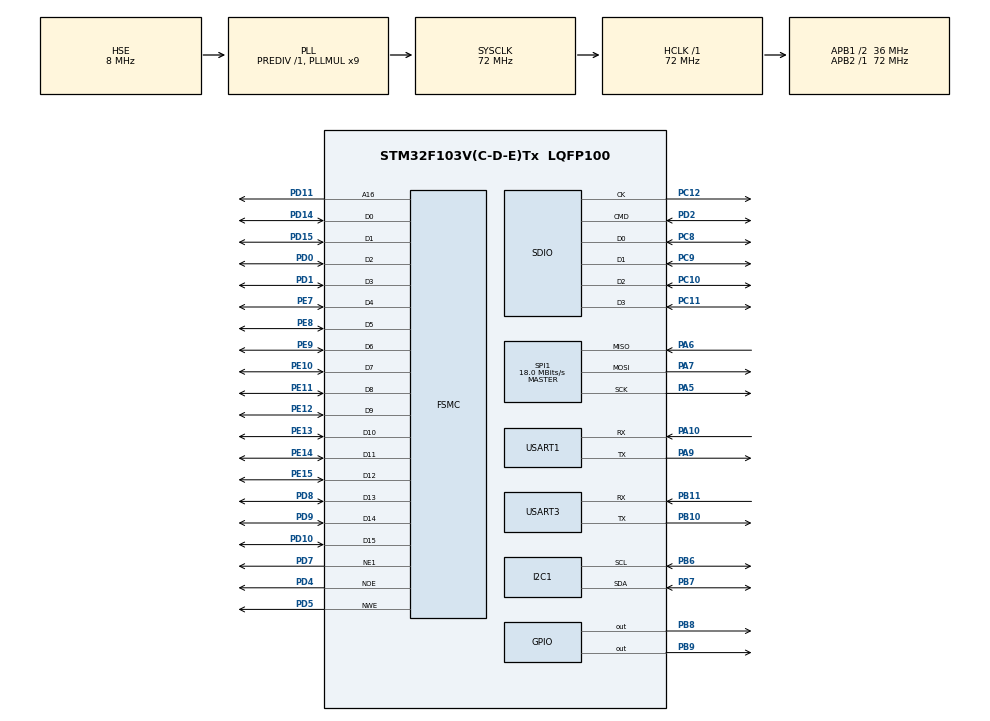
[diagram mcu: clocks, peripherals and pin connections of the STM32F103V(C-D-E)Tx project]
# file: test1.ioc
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Dma.MEMTOMEM.0.Direction=DMA_MEMORY_TO_MEMORY
Dma.MEMTOMEM.0.Instance=DMA1_Channel6
Dma.MEMTOMEM.0.MemDataAlignment=DMA_MDATAALIGN_HALFWORD
Dma.MEMTOMEM.0.MemInc=DMA_MINC_ENABLE
Dma.MEMTOMEM.0.Mode=DMA_NORMAL
Dma.MEMTOMEM.0.PeriphDataAlignment=DMA_PDATAALIGN_HALFWORD
Dma.MEMTOMEM.0.PeriphInc=DMA_PINC_ENABLE
Dma.MEMTOMEM.0.Priority=DMA_PRIORITY_VERY_HIGH
Dma.Request0=MEMTOMEM
Dma.Request1=SDIO
Dma.SDIO.1.Direction=DMA_PERIPH_TO_MEMORY
Dma.SDIO.1.Instance=DMA2_Channel4
Dma.SDIO.1.MemDataAlignment=DMA_MDATAALIGN_WORD
Dma.SDIO.1.MemInc=DMA_MINC_ENABLE
Dma.SDIO.1.Mode=DMA_NORMAL
Dma.SDIO.1.PeriphDataAlignment=DMA_PDATAALIGN_WORD
Dma.SDIO.1.PeriphInc=DMA_PINC_DISABLE
Dma.SDIO.1.Priority=DMA_PRIORITY_LOW
FATFS._FS_LOCK=4
FATFS._FS_REENTRANT=0
Mcu.Family=STM32F1
Mcu.Name=STM32F103V(C-D-E)Tx
Mcu.Package=LQFP100
NVIC.DMA1_Channel6_IRQn=true\:0\:0\:false\:false\:true\:true\:true\:true
NVIC.DMA2_Channel4_5_IRQn=true\:0\:0\:false\:false\:true\:false\:true\:true
NVIC.PriorityGroup=NVIC_PRIORITYGROUP_4
NVIC.RTC_IRQn=true\:0\:0\:false\:false\:true\:true\:true\:true
NVIC.SDIO_IRQn=true\:0\:0\:false\:false\:true\:true\:true\:true
NVIC.TIM1_UP_IRQn=true\:15\:0\:true\:false\:true\:false\:true\:true
NVIC.TimeBase=TIM1_UP_IRQn
NVIC.TimeBaseIP=TIM1
NVIC.USART3_IRQn=true\:0\:0\:false\:false\:true\:true\:true\:true
OSC_IN.Mode=HSE-External-Oscillator
OSC_IN.Signal=RCC_OSC_IN
OSC_OUT.Mode=HSE-External-Oscillator
OSC_OUT.Signal=RCC_OSC_OUT
PA10.Mode=Asynchronous
PA10.Signal=USART1_RX
PA13.Mode=Serial_Wire
PA13.Signal=SYS_JTMS-SWDIO
PA14.Mode=Serial_Wire
PA14.Signal=SYS_JTCK-SWCLK
PA5.Mode=Full_Duplex_Master
PA5.Signal=SPI1_SCK
PA6.Mode=Full_Duplex_Master
PA6.Signal=SPI1_MISO
PA7.Mode=Full_Duplex_Master
PA7.Signal=SPI1_MOSI
PA9.Mode=Asynchronous
PA9.Signal=USART1_TX
PB10.Mode=Asynchronous
PB10.Signal=USART3_TX
PB11.Mode=Asynchronous
PB11.Signal=USART3_RX
PB6.Mode=I2C
PB6.Signal=I2C1_SCL
PB7.Mode=I2C
PB7.Signal=I2C1_SDA
PB8.GPIO_PuPd=GPIO_PULLDOWN
PB8.GPIO_Speed=GPIO_SPEED_FREQ_HIGH
PB8.Signal=GPIO_Output
PB9.GPIO_PuPd=GPIO_PULLUP
PB9.GPIO_Speed=GPIO_SPEED_FREQ_HIGH
PB9.Signal=GPIO_Output
PC10.Mode=SD_4_bits_Wide_bus
PC10.Signal=SDIO_D2
PC11.Mode=SD_4_bits_Wide_bus
PC11.Signal=SDIO_D3
PC12.Mode=SD_4_bits_Wide_bus
PC12.Signal=SDIO_CK
PC14-OSC32_IN.Mode=LSE-External-Oscillator
PC14-OSC32_IN.Signal=RCC_OSC32_IN
PC15-OSC32_OUT.Mode=LSE-External-Oscillator
PC15-OSC32_OUT.Signal=RCC_OSC32_OUT
PC8.Mode=SD_4_bits_Wide_bus
PC8.Signal=SDIO_D0
PC9.Mode=SD_4_bits_Wide_bus
PC9.Signal=SDIO_D1
PD0.Mode=16b-d1
PD0.Signal=FSMC_D2
PD1.Mode=16b-d1
PD1.Signal=FSMC_D3
PD10.Mode=16b-d1
PD10.Signal=FSMC_D15
PD11.Mode=A16_1
PD11.Signal=FSMC_A16
PD14.Mode=16b-d1
PD14.Signal=FSMC_D0
PD15.Mode=16b-d1
PD15.Signal=FSMC_D1
PD2.Mode=SD_4_bits_Wide_bus
PD2.Signal=SDIO_CMD
PD4.Mode=Lcd1
PD4.Signal=FSMC_NOE
PD5.Mode=Lcd1
PD5.Signal=FSMC_NWE
PD7.Mode=NorPsramChipSelect1_1
PD7.Signal=FSMC_NE1
PD8.Mode=16b-d1
PD8.Signal=FSMC_D13
PD9.Mode=16b-d1
PD9.Signal=FSMC_D14
PE10.Mode=16b-d1
PE10.Signal=FSMC_D7
PE11.Mode=16b-d1
PE11.Signal=FSMC_D8
PE12.Mode=16b-d1
PE12.Signal=FSMC_D9
PE13.Mode=16b-d1
PE13.Signal=FSMC_D10
PE14.Mode=16b-d1
PE14.Signal=FSMC_D11
PE15.Mode=16b-d1
PE15.Signal=FSMC_D12
PE7.Mode=16b-d1
PE7.Signal=FSMC_D4
PE8.Mode=16b-d1
PE8.Signal=FSMC_D5
PE9.Mode=16b-d1
PE9.Signal=FSMC_D6
ProjectManager.HeapSize=0x200
ProjectManager.StackSize=0x400
ProjectManager.TargetToolchain=CMake
RCC.AHBFreq_Value=72000000
RCC.APB1CLKDivider=RCC_HCLK_DIV2
RCC.APB1Freq_Value=36000000
RCC.APB1TimFreq_Value=72000000
RCC.APB2Freq_Value=72000000
RCC.APB2TimFreq_Value=72000000
RCC.EnbaleCSS=true
RCC.HCLKFreq_Value=72000000
RCC.PLLMUL=RCC_PLL_MUL9
RCC.PLLSourceVirtual=RCC_PLLSOURCE_HSE
RCC.RTCClockSelection=RCC_RTCCLKSOURCE_LSE
RCC.SYSCLKFreq_VALUE=72000000
RCC.SYSCLKSource=RCC_SYSCLKSOURCE_PLLCLK
RCC.USBFreq_Value=72000000
RTC.Date=11
RTC.Format=RTC_FORMAT_BIN
RTC.Hours=22
RTC.Minutes=8
RTC.Month=RTC_MONTH_MARCH
RTC.WeekDay=RTC_WEEKDAY_WEDNESDAY
RTC.Year=26
SDIO.ClockBypass=SDIO_CLOCK_BYPASS_DISABLE
SDIO.ClockDiv=0
SDIO.ClockPowerSave=SDIO_CLOCK_POWER_SAVE_ENABLE
SDIO.HardwareFlowControl=SDIO_HARDWARE_FLOW_CONTROL_ENABLE
SPI1.BaudRatePrescaler=SPI_BAUDRATEPRESCALER_4
SPI1.CalculateBaudRate=18.0 MBits/s
SPI1.Direction=SPI_DIRECTION_2LINES
SPI1.Mode=SPI_MODE_MASTER
SPI1.VirtualType=VM_MASTER
USART1.VirtualMode=VM_ASYNC
USART3.VirtualMode=VM_ASYNC
VP_FATFS_VS_SDIO.Mode=SDIO
VP_RTC_VS_RTC_Activate.Mode=RTC_Enabled
VP_RTC_VS_RTC_Calendar.Mode=RTC_Calendar
VP_SYS_VS_tim1.Mode=TIM1
board=custom

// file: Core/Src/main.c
/* USER CODE BEGIN Header */
/**
  ******************************************************************************
  * @file           : main.c
  * @brief          : Main program body
  ******************************************************************************
  * @attention
  *
  * Copyright (c) 2025 STMicroelectronics.
  * All rights reserved.
  *
  * This software is licensed under terms that can be found in the LICENSE file
  * in the root directory of this software component.
  * If no LICENSE file comes with this software, it is provided AS-IS.
  *
  ******************************************************************************
  */
/* USER CODE END Header */
#include "main.h"
#include "dma.h"
#include "fatfs.h"
#include "i2c.h"
#include "rtc.h"
#include "sdio.h"
#include "spi.h"
#include "usart.h"
#include "gpio.h"
#include "fsmc.h"

/* USER CODE BEGIN Includes */
#include "log.h"
#include "string.h"
// #include "lvgl.h"
// #include "maze.h"
// #include "ESP8266.h"
/* USER CODE END Includes */

void SystemClock_Config(void);

int main(void)
{

  /* MCU Configuration--------------------------------------------------------*/

  /* Reset of all peripherals, Initializes the Flash interface and the Systick. */
  HAL_Init();

  /* Configure the system clock */
  SystemClock_Config();

  /* Initialize all configured peripherals */
  MX_GPIO_Init();
  MX_DMA_Init();
  MX_FSMC_Init();
  MX_SDIO_SD_Init();
  MX_FATFS_Init();
  MX_RTC_Init();
  MX_SPI1_Init();
  MX_USART1_UART_Init();
  MX_I2C1_Init();
  MX_USART3_UART_Init();
  /* USER CODE BEGIN 2 */

  log_Init();
    // FATFS fs;
    // FIL file;
    // FRESULT res;

    // // 挂载文件系统
    // res = f_mount(&fs, "", 1);
    // if (res != FR_OK) {
    //     log_Error("FATFS 挂载失败: %d", res);
    // }
    // HAL_Delay(100); // 确保SD卡初始化完成
    // // 创建并写入文件
    // res = f_open(&file, "test.txt", FA_CREATE_ALWAYS | FA_WRITE);
    // if (res != FR_OK) {
    //     log_Error("FATFS 打开文件失败: %d", res);
    // }
    // HAL_Delay(100); // 确保文件系统初始化完成
    // const char* text = "Hello, FATFS!";
    // UINT bytesWritten;
    // res = f_write(&file, text, strlen(text), &bytesWritten);
    // if (res != FR_OK || bytesWritten != strlen(text)) {
    //     log_Error("FATFS 写入文件失败: %d", res);
    //     f_close(&file);
    // }
    // else
    // {
    //     log_Debug("FATFS 文件写入成功");
    // }
    // f_close(&file);

  // if(Timer_Init() != STATUS_OK)
  // {
  //     log_Error("Failed to initialize timer.");
  //     Error_Handler();
  // }
  // lv_test();
  // log_Debug("LVGL test completed.");
  // Maze_Init();
  // Maze_Test();
  // log_Debug("Maze test completed.");
  // ESP8266_Test();
  /* USER CODE END 2 */

  /* Infinite loop */
  /* USER CODE BEGIN WHILE */
  while (1)
  {
    // lv_timer_handler(); // 处理LVGL任务
    // HAL_Delay(1); // 延时，避免占用过多CPU资源
    /* USER CODE END WHILE */

  }
}

void SystemClock_Config(void)
{
  RCC_OscInitTypeDef RCC_OscInitStruct = {0};
  RCC_ClkInitTypeDef RCC_ClkInitStruct = {0};
  RCC_PeriphCLKInitTypeDef PeriphClkInit = {0};

  /** Initializes the RCC Oscillators according to the specified parameters
  * in the RCC_OscInitTypeDef structure.
  */
  RCC_OscInitStruct.OscillatorType = RCC_OSCILLATORTYPE_HSE|RCC_OSCILLATORTYPE_LSE;
  RCC_OscInitStruct.HSEState = RCC_HSE_ON;
  RCC_OscInitStruct.HSEPredivValue = RCC_HSE_PREDIV_DIV1;
  RCC_OscInitStruct.LSEState = RCC_LSE_ON;
  RCC_OscInitStruct.HSIState = RCC_HSI_ON;
  RCC_OscInitStruct.PLL.PLLState = RCC_PLL_ON;
  RCC_OscInitStruct.PLL.PLLSource = RCC_PLLSOURCE_HSE;
  RCC_OscInitStruct.PLL.PLLMUL = RCC_PLL_MUL9;
  if (HAL_RCC_OscConfig(&RCC_OscInitStruct) != HAL_OK)
  {
    Error_Handler();
  }

  /** Initializes the CPU, AHB and APB buses clocks
  */
  RCC_ClkInitStruct.ClockType = RCC_CLOCKTYPE_HCLK|RCC_CLOCKTYPE_SYSCLK
                              |RCC_CLOCKTYPE_PCLK1|RCC_CLOCKTYPE_PCLK2;
  RCC_ClkInitStruct.SYSCLKSource = RCC_SYSCLKSOURCE_PLLCLK;
  RCC_ClkInitStruct.AHBCLKDivider = RCC_SYSCLK_DIV1;
  RCC_ClkInitStruct.APB1CLKDivider = RCC_HCLK_DIV2;
  RCC_ClkInitStruct.APB2CLKDivider = RCC_HCLK_DIV1;

  if (HAL_RCC_ClockConfig(&RCC_ClkInitStruct, FLASH_LATENCY_2) != HAL_OK)
  {
    Error_Handler();
  }
  PeriphClkInit.PeriphClockSelection = RCC_PERIPHCLK_RTC;
  PeriphClkInit.RTCClockSelection = RCC_RTCCLKSOURCE_LSE;
  if (HAL_RCCEx_PeriphCLKConfig(&PeriphClkInit) != HAL_OK)
  {
    Error_Handler();
  }

  /** Enables the Clock Security System
  */
  HAL_RCC_EnableCSS();
}

void HAL_TIM_PeriodElapsedCallback(TIM_HandleTypeDef *htim)
{
  if (htim->Instance == TIM1)
  {
    HAL_IncTick();
  }
}

void Error_Handler(void)
{
  /* USER CODE BEGIN Error_Handler_Debug */
  /* User can add his own implementation to report the HAL error return state */
  __disable_irq();
  while (1)
  {
    //PB1设置为低电平，点亮LED
    __HAL_RCC_GPIOB_CLK_ENABLE();
    //配置PB1时钟
    GPIO_InitTypeDef GPIO_Initure;
    GPIO_Initure.Pin = GPIO_PIN_1;               //PB1
    GPIO_Initure.Mode = GPIO_MODE_OUTPUT_PP;     //推挽输出
    GPIO_Initure.Pull = GPIO_NOPULL;              //不带上下拉
    GPIO_Initure.Speed = GPIO_SPEED_FREQ_HIGH;    //高速
    HAL_GPIO_Init(GPIOB, &GPIO_Initure);         //初始化PB1

    HAL_GPIO_TogglePin(GPIOB, GPIO_PIN_1); // 切换 LED 状态
    HAL_Delay(500); // 延时 500ms
  }
  /* USER CODE END Error_Handler_Debug */
}
